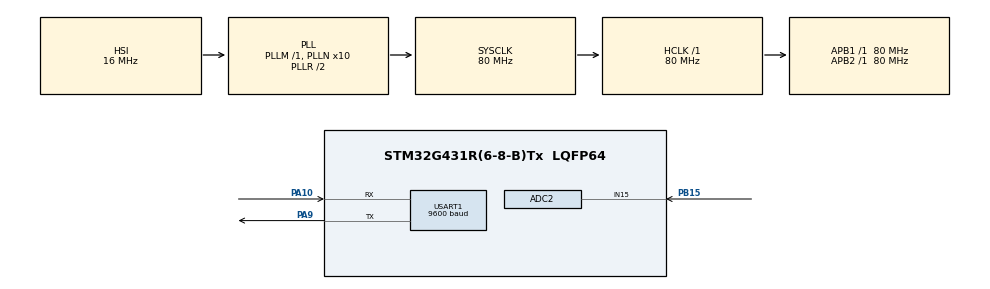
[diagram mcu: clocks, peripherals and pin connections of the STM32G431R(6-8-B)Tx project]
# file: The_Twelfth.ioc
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ADC2.Channel-0\#ChannelRegularConversion=ADC_CHANNEL_15
ADC2.NbrOfConversionFlag=1
ADC2.OffsetNumber-0\#ChannelRegularConversion=ADC_OFFSET_NONE
ADC2.Rank-0\#ChannelRegularConversion=1
ADC2.SamplingTime-0\#ChannelRegularConversion=ADC_SAMPLETIME_2CYCLES_5
Mcu.Family=STM32G4
Mcu.Name=STM32G431R(6-8-B)Tx
Mcu.Package=LQFP64
NVIC.PriorityGroup=NVIC_PRIORITYGROUP_4
NVIC.USART1_IRQn=true\:1\:0\:true\:false\:true\:true\:true
PA10.Mode=Asynchronous
PA10.Signal=USART1_RX
PA9.Mode=Asynchronous
PA9.Signal=USART1_TX
PB15.Mode=IN15-Single-Ended
PB15.Signal=ADC2_IN15
ProjectManager.HeapSize=0x200
ProjectManager.StackSize=0x400
ProjectManager.TargetToolchain=MDK-ARM V5.32
RCC.ADC12Freq_Value=80000000
RCC.AHBFreq_Value=80000000
RCC.APB1Freq_Value=80000000
RCC.APB1TimFreq_Value=80000000
RCC.APB2Freq_Value=80000000
RCC.APB2TimFreq_Value=80000000
RCC.CortexFreq_Value=80000000
RCC.EXTERNAL_CLOCK_VALUE=12288000
RCC.HCLKFreq_Value=80000000
RCC.HSE_VALUE=8000000
RCC.HSI48_VALUE=48000000
RCC.HSI_VALUE=16000000
RCC.LSE_VALUE=32768
RCC.PLLN=10
RCC.SYSCLKFreq_VALUE=80000000
RCC.SYSCLKSource=RCC_SYSCLKSOURCE_PLLCLK
RCC.USBFreq_Value=80000000
RCC.VCOOutputFreq_Value=160000000
USART1.BaudRate=9600
USART1.VirtualMode-Asynchronous=VM_ASYNC
VP_SYS_VS_DBSignals.Mode=DisableDeadBatterySignals
board=custom

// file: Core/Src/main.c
/* USER CODE BEGIN Header */
/**
  ******************************************************************************
  * @file           : main.c
  * @brief          : Main program body
  ******************************************************************************
  * @attention
  *
  * Copyright (c) 2022 STMicroelectronics.
  * All rights reserved.
  *
  * This software is licensed under terms that can be found in the LICENSE file
  * in the root directory of this software component.
  * If no LICENSE file comes with this software, it is provided AS-IS.
  *
  ******************************************************************************
  */
/* USER CODE END Header */
#include "main.h"
#include "adc.h"
#include "usart.h"
#include "gpio.h"

/* USER CODE BEGIN Includes */
#include "stdio.h"
#include "string.h"
#include "lcd.h"
/* USER CODE END Includes */

/* USER CODE BEGIN PV */
__IO uint32_t uwTick_USART_Set_Point;
__IO uint32_t uwTick_Lcd_Set_Point;
__IO uint32_t uwTick_ADC_Set_Point;
uint32_t Num;

uint8_t RX_BUF[200];
uint8_t Rx_Counter;
uint8_t rx_buffer;
uint8_t Rx_Flag;
uint8_t pucStr[21];
uint16_t a_buf[5];
uint16_t q_a_buf[5];
uint16_t temp;
uint8_t i;
char str[40];
double ADC_Value;
/* USER CODE END PV */

void SystemClock_Config(void);
/* USER CODE BEGIN PFP */
void USART_Proc(void);
void LCD_Proc(void);
void ADC_Proc(void);
/* USER CODE END PFP */

int main(void)
{

  /* MCU Configuration--------------------------------------------------------*/

  /* Reset of all peripherals, Initializes the Flash interface and the Systick. */
  HAL_Init();

  /* Configure the system clock */
  SystemClock_Config();

  /* Initialize all configured peripherals */
  MX_GPIO_Init();
  MX_USART1_UART_Init();
  MX_ADC2_Init();
  /* USER CODE BEGIN 2 */
	LCD_Init();
	LCD_Clear(Black);
	LCD_SetBackColor(Black);
	LCD_SetTextColor(White);

	HAL_UART_Receive_IT(&huart1, &rx_buffer, 1);
  /* USER CODE END 2 */

  /* Infinite loop */
  while (1)
  {

    /* USER CODE BEGIN 3 */
		ADC_Proc();
		LCD_Proc();
		USART_Proc();
  }
  /* USER CODE END 3 */
}

void SystemClock_Config(void)
{
  RCC_OscInitTypeDef RCC_OscInitStruct = {0};
  RCC_ClkInitTypeDef RCC_ClkInitStruct = {0};

  /** Configure the main internal regulator output voltage
  */
  HAL_PWREx_ControlVoltageScaling(PWR_REGULATOR_VOLTAGE_SCALE1);
  /** Initializes the RCC Oscillators according to the specified parameters
  * in the RCC_OscInitTypeDef structure.
  */
  RCC_OscInitStruct.OscillatorType = RCC_OSCILLATORTYPE_HSI;
  RCC_OscInitStruct.HSIState = RCC_HSI_ON;
  RCC_OscInitStruct.HSICalibrationValue = RCC_HSICALIBRATION_DEFAULT;
  RCC_OscInitStruct.PLL.PLLState = RCC_PLL_ON;
  RCC_OscInitStruct.PLL.PLLSource = RCC_PLLSOURCE_HSI;
  RCC_OscInitStruct.PLL.PLLM = RCC_PLLM_DIV1;
  RCC_OscInitStruct.PLL.PLLN = 10;
  RCC_OscInitStruct.PLL.PLLP = RCC_PLLP_DIV2;
  RCC_OscInitStruct.PLL.PLLQ = RCC_PLLQ_DIV2;
  RCC_OscInitStruct.PLL.PLLR = RCC_PLLR_DIV2;
  if (HAL_RCC_OscConfig(&RCC_OscInitStruct) != HAL_OK)
  {
    Error_Handler();
  }
  /** Initializes the CPU, AHB and APB buses clocks
  */
  RCC_ClkInitStruct.ClockType = RCC_CLOCKTYPE_HCLK|RCC_CLOCKTYPE_SYSCLK
                              |RCC_CLOCKTYPE_PCLK1|RCC_CLOCKTYPE_PCLK2;
  RCC_ClkInitStruct.SYSCLKSource = RCC_SYSCLKSOURCE_PLLCLK;
  RCC_ClkInitStruct.AHBCLKDivider = RCC_SYSCLK_DIV1;
  RCC_ClkInitStruct.APB1CLKDivider = RCC_HCLK_DIV1;
  RCC_ClkInitStruct.APB2CLKDivider = RCC_HCLK_DIV1;

  if (HAL_RCC_ClockConfig(&RCC_ClkInitStruct, FLASH_LATENCY_2) != HAL_OK)
  {
    Error_Handler();
  }
}

/* USER CODE BEGIN 4 */
void ADC_Proc(void)
{
	if(uwTick - uwTick_ADC_Set_Point <= 1000)
		return;
	uwTick_ADC_Set_Point = uwTick;

	//ADC_Value = Get_R37_Value() / 4095. * 3.3;
	Num++;
	a_buf[i++] = Num;
	if(i >= 5)
		i = 0;

	for(int j = 0; j < 5; j++)
	{
		q_a_buf[j] = a_buf[j];
	}
	for(int k = 0; k <= 2; k++)
	{
		for(int j = 0; k < 5 - j - 1; j++)
		{
			if(q_a_buf[j] > q_a_buf[j + 1])
			{
				temp = q_a_buf[j];
				q_a_buf[j] = q_a_buf[j + 1];
				q_a_buf[j + 1] = temp;
			}
		}
	}
}

void LCD_Proc(void)
{
	if(uwTick - uwTick_Lcd_Set_Point <= 100)
		return;
	uwTick_Lcd_Set_Point = uwTick;

	sprintf((char*)pucStr, "ADC:%3.2lf", ADC_Value);
	LCD_DisplayStringLine(Line1, (u8*)pucStr);
}

void USART_Proc(void)
{
	if(uwTick - uwTick_USART_Set_Point <= 100)
		return;
	uwTick_USART_Set_Point = uwTick;

	if(Rx_Flag)
	{
//		if(strcmp((const char*)RX_BUF, "a?") == 0)
//		{
//			sprintf(str, "a\r\n");
//			HAL_UART_Transmit(&huart1, (uint8_t*)str, strlen(str), 50);
//		}
//		else if(strcmp((const char*)RX_BUF, "b?") == 0)
//		{
//			sprintf(str, "b\r\n");
//			HAL_UART_Transmit(&huart1, (uint8_t*)str, strlen(str), 50);
//		}
//		else if(strcmp((const char*)RX_BUF, "aa?") == 0)
//		{
//			sprintf(str, "aa:%d-%d-%d-%d-%d\r\n", a_buf[0], a_buf[1], a_buf[2], a_buf[3], a_buf[4]);
//			HAL_UART_Transmit(&huart1, (uint8_t*)str, strlen(str), 50);
//		}
//		else if(strcmp((const char*)RX_BUF, "bb?") == 0)
//		{
//			sprintf(str, "bb\r\n");
//			HAL_UART_Transmit(&huart1, (uint8_t*)str, strlen(str), 50);
//		}
//		else if(strcmp((const char*)RX_BUF, "qa?") == 0)
//		{
//			sprintf(str, "qa:%d-%d-%d-%d-%d\r\n", q_a_buf[0], q_a_buf[1], q_a_buf[2], q_a_buf[3], q_a_buf[4]);
//			HAL_UART_Transmit(&huart1, (uint8_t*)str, strlen(str), 50);
//		}
//		else if(strcmp((const char*)RX_BUF, "qb?") == 0)
//		{
//			sprintf(str, "qb\r\n");
//			HAL_UART_Transmit(&huart1, (uint8_t*)str, strlen(str), 50);
//		}
//		else
//		{
//			sprintf(str, "Error\r\n");
//			HAL_UART_Transmit(&huart1, (uint8_t*)str, strlen(str), 50);
//		}

		if(strcmp((const char*)RX_BUF, "1") == 0)
		{
			sprintf(str, "1\r\n");
			HAL_UART_Transmit(&huart1, (uint8_t*)str, strlen(str), 50);
		}
		else if(strcmp((const char*)RX_BUF, "2") == 0)
		{
			sprintf(str, "2\r\n");
			HAL_UART_Transmit(&huart1, (uint8_t*)str, strlen(str), 50);
		}
		else
		{
			sprintf(str, "0\r\n");
			HAL_UART_Transmit(&huart1, (uint8_t*)str, strlen(str), 50);
		}

		Rx_Flag = 0;
		Rx_Counter = 0;
		memset(RX_BUF, 0, sizeof(RX_BUF));
	}
}

void HAL_UART_RxCpltCallback(UART_HandleTypeDef *huart)
{
	Rx_Flag = 1;
	RX_BUF[Rx_Counter++] = rx_buffer;
	HAL_UART_Receive_IT(&huart1, &rx_buffer, 1);
}
/* USER CODE END 4 */

void Error_Handler(void)
{
  __disable_irq();
  while (1)
  {
  }
}
